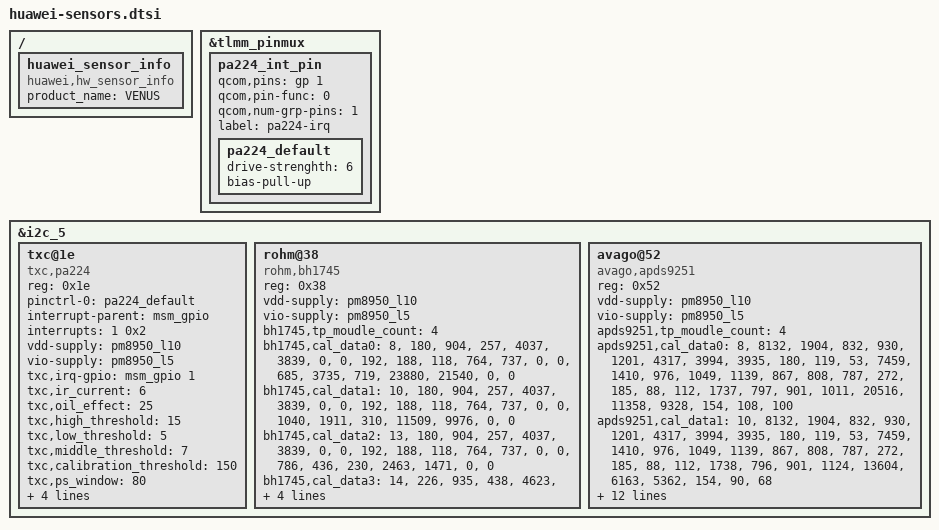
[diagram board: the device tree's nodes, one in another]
/*use fromdos convert file format to linux*/
/* Copyright (c) 2013 The Linux Foundation. All rights reserved.
 *
 * This program is free software; you can redistribute it and/or modify
 * it under the terms of the GNU General Public License version 2 and
 * only version 2 as published by the Free Software Foundation.
 *
 * This program is distributed in the hope that it will be useful,
 * but WITHOUT ANY WARRANTY; without even the implied warranty of
 * MERCHANTABILITY or FITNESS FOR A PARTICULAR PURPOSE.  See the
 * GNU General Public License for more details.
 */
&tlmm_pinmux {

	pa224_int_pin {
		qcom,pins = <&gp 1>;
		qcom,pin-func = <0>;
		qcom,num-grp-pins = <1>;
		label = "pa224-irq";
		pa224_default: pa224_default {
			drive-strenghth = <6>;
			bias-pull-up;
		};
	};

};

&i2c_5{
	txc@1e {
		compatible = "txc,pa224";
		reg = <0x1e>;
		pinctrl-names = "default";
		pinctrl-0 = <&pa224_default>;
		interrupt-parent = <&msm_gpio>;
		interrupts = <1 0x2>;
		vdd-supply = <&pm8950_l10>;
		vio-supply = <&pm8950_l5>;
		txc,irq-gpio = <&msm_gpio 1 0x2>;
		/*IR CURRENT 10MA*/
		txc,ir_current = <6>;
		txc,oil_effect = <25>;
		txc,high_threshold = <15>;
		txc,low_threshold = <5>;
		txc,middle_threshold = <7>;
		txc,calibration_threshold = <150>;
		txc,ps_window = <80>;
		txc,ps_wave = <40>;
		txc,ps_defalt_crosstalk = <50>;
		txc,i2c-scl-gpio = <&msm_gpio 19 0x0>;
		txc,i2c-sda-gpio = <&msm_gpio 18 0x0>;
	};
	rohm@38 {
		compatible = "rohm,bh1745";
		reg = <0x38>;
		vdd-supply = <&pm8950_l10>;
		vio-supply = <&pm8950_l5>;
		bh1745,tp_moudle_count = <4>;
		/*[module_id] [golden judge] r[0] r[1] g[0] g[1] b[0] b[1]*/
		bh1745,cal_data0 =  "8","180","904","257","4037","3839","0","0",
		/*[white judge] r[0] r[1] g[0] g[1] b[0] b[1]*/
		"192","188","118","764","737","0","0",
		/*[black judge] r[0] r[1] g[0] g[1] b[0] b[1]*/
		"685","3735","719","23880","21540","0","0";
		/*[module_id] [golden judge] r[0] r[1] g[0] g[1] b[0] b[1]*/
		bh1745,cal_data1 =  "10","180","904","257","4037","3839","0","0",

		/*[white judge] r[0] r[1] g[0] g[1] b[0] b[1]*/
		"192","188","118","764","737","0","0",
		/*[black judge] r[0] r[1] g[0] g[1] b[0] b[1]*/
		"1040","1911","310","11509","9976","0","0";
		/*[module_id] [golden judge] r[0] r[1] g[0] g[1] b[0] b[1]*/
		bh1745,cal_data2 = "13","180","904","257","4037","3839","0","0",
		/*[white judge] r[0] r[1] g[0] g[1] b[0] b[1]*/
		"192","188","118","764","737","0","0",
		/*[black judge] r[0] r[1] g[0] g[1] b[0] b[1]*/
		"786","436","230","2463","1471","0","0";
		/*[module_id] [golden judge] r[0] r[1] g[0] g[1] b[0] b[1]*/
		bh1745,cal_data3 = "14","226","935","438","4623","4895","0","0",
		/*[white judge] r[0] r[1] g[0] g[1] b[0] b[1]*/
		"200","187","114","761","641","0","0",
		/*[black judge] r[0] r[1] g[0] g[1] b[0] b[1]*/
		"988","307","185","2038","1100","0","0";
		bh1745,i2c-scl-gpio = <&msm_gpio 19 0x0>;
		bh1745,i2c-sda-gpio = <&msm_gpio 18 0x0>;
	};
	avago@52 {
		compatible = "avago,apds9251";
		reg = <0x52>;
		vdd-supply = <&pm8950_l10>;
		vio-supply = <&pm8950_l5>;
		apds9251,tp_moudle_count = <4>;
		/*[module_id] [CCT_M] [CCT_N] [H] [A] [D] [LUX_P] [LUX_Q] [LUX_R] [cofficient0] [cofficient1] [cofficient2]*/
		apds9251,cal_data0 = "8","8132","1904","832","930","1201","4317","3994","3935","180","119","53",
		/*[CCT_M] [CCT_N] [H] [A] [D] [LUX_P] [LUX_Q] [LUX_R] [cofficient0] [cofficient1] [cofficient2]*/
		"7459","1410","976","1049","1139","867","808","787","272","185","88",
		/*[CCT_M] [CCT_N] [H] [A] [D] [LUX_P] [LUX_Q] [LUX_R] [cofficient0] [cofficient1] [cofficient2]*/
		"112","1737","797","901","1011","20516","11358","9328","154","108","100";
		/*[module_id] [CCT_M] [CCT_N] [H] [A] [D] [LUX_P] [LUX_Q] [LUX_R] [cofficient0] [cofficient1] [cofficient2]*/
		apds9251,cal_data1 = "10","8132","1904","832","930","1201","4317","3994","3935","180","119","53",
		/*[CCT_M] [CCT_N] [H] [A] [D] [LUX_P] [LUX_Q] [LUX_R] [cofficient0] [cofficient1] [cofficient2]*/
		"7459","1410","976","1049","1139","867","808","787","272","185","88",
		/*[CCT_M] [CCT_N] [H] [A] [D] [LUX_P] [LUX_Q] [LUX_R] [cofficient0] [cofficient1] [cofficient2]*/
		"112","1738","796","901","1124","13604","6163","5362","154","90","68";
		/*[module_id] [CCT_M] [CCT_N] [H] [A] [D] [LUX_P] [LUX_Q] [LUX_R] [cofficient0] [cofficient1] [cofficient2]*/
		apds9251,cal_data2 ="13","8132","1904","832","930","1201","4317","3994","3935","180","119","53",
		/*[CCT_M] [CCT_N] [H] [A] [D] [LUX_P] [LUX_Q] [LUX_R] [cofficient0] [cofficient1] [cofficient2]*/
		"7459","1410","976","1049","1139","867","808","787","272","185","88",
		/*[CCT_M] [CCT_N] [H] [A] [D] [LUX_P] [LUX_Q] [LUX_R] [cofficient0] [cofficient1] [cofficient2]*/
		"12535","1086","821","941","1142","3000","1500","1000","718","730","247";
		/*[module_id] [CCT_M] [CCT_N] [H] [A] [D] [LUX_P] [LUX_Q] [LUX_R] [cofficient0] [cofficient1] [cofficient2]*/
		apds9251,cal_data3 ="14","10079","1804","806","930","1160","4970","4100","4465","182","124","56",
		/*[CCT_M] [CCT_N] [H] [A] [D] [LUX_P] [LUX_Q] [LUX_R] [cofficient0] [cofficient1] [cofficient2]*/
		"6240","1954","844","940","1218","802","795","720","294","193","86",
		/*[CCT_M] [CCT_N] [H] [A] [D] [LUX_P] [LUX_Q] [LUX_R] [cofficient0] [cofficient1] [cofficient2]*/
		"3711","798","1392","1639","1778","3080","1256","1010","1013","779","370";
		apds9251,i2c-scl-gpio = <&msm_gpio 19 0x0>;
		apds9251,i2c-sda-gpio = <&msm_gpio 18 0x0>;
	};
};
 / {
	huawei_sensor_info {
		compatible = "huawei,hw_sensor_info";
		product_name = "VENUS";
	};
};
